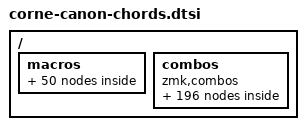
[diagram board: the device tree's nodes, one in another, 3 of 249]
/* Auto-generated by scripts/gen-chords-dual.py — do not edit by hand */
/* CORNE-canonical dual-layout chords: 50 words × 2 layouts × 2 space keys */

/ {
    macros {
        wm_the: wm_the {
            compatible = "zmk,behavior-macro";
            #binding-cells = <0>;
            wait-ms = <0>;
            tap-ms = <0>;
            bindings = <&kp T &kp H &kp E &kp SPACE>;
        };

        wm_be: wm_be {
            compatible = "zmk,behavior-macro";
            #binding-cells = <0>;
            wait-ms = <0>;
            tap-ms = <0>;
            bindings = <&kp B &kp E &kp SPACE>;
        };

        wm_to: wm_to {
            compatible = "zmk,behavior-macro";
            #binding-cells = <0>;
            wait-ms = <0>;
            tap-ms = <0>;
            bindings = <&kp T &kp O &kp SPACE>;
        };

        wm_and: wm_and {
            compatible = "zmk,behavior-macro";
            #binding-cells = <0>;
            wait-ms = <0>;
            tap-ms = <0>;
            bindings = <&kp A &kp N &kp D &kp SPACE>;
        };

        wm_of: wm_of {
            compatible = "zmk,behavior-macro";
            #binding-cells = <0>;
            wait-ms = <0>;
            tap-ms = <0>;
            bindings = <&kp O &kp F &kp SPACE>;
        };

        wm_in: wm_in {
            compatible = "zmk,behavior-macro";
            #binding-cells = <0>;
            wait-ms = <0>;
            tap-ms = <0>;
            bindings = <&kp I &kp N &kp SPACE>;
        };

        wm_have: wm_have {
            compatible = "zmk,behavior-macro";
            #binding-cells = <0>;
            wait-ms = <0>;
            tap-ms = <0>;
            bindings = <&kp H &kp A &kp V &kp E &kp SPACE>;
        };

        wm_that: wm_that {
            compatible = "zmk,behavior-macro";
            #binding-cells = <0>;
            wait-ms = <0>;
            tap-ms = <0>;
            bindings = <&kp T &kp H &kp A &kp T &kp SPACE>;
        };

        wm_for: wm_for {
            compatible = "zmk,behavior-macro";
            #binding-cells = <0>;
            wait-ms = <0>;
            tap-ms = <0>;
            bindings = <&kp F &kp O &kp R &kp SPACE>;
        };

        wm_not: wm_not {
            compatible = "zmk,behavior-macro";
            #binding-cells = <0>;
            wait-ms = <0>;
            tap-ms = <0>;
            bindings = <&kp N &kp O &kp T &kp SPACE>;
        };

        wm_with: wm_with {
            compatible = "zmk,behavior-macro";
            #binding-cells = <0>;
            wait-ms = <0>;
            tap-ms = <0>;
            bindings = <&kp W &kp I &kp T &kp H &kp SPACE>;
        };

        wm_you: wm_you {
            compatible = "zmk,behavior-macro";
            #binding-cells = <0>;
            wait-ms = <0>;
            tap-ms = <0>;
            bindings = <&kp Y &kp O &kp U &kp SPACE>;
        };

        wm_this: wm_this {
            compatible = "zmk,behavior-macro";
            #binding-cells = <0>;
            wait-ms = <0>;
            tap-ms = <0>;
            bindings = <&kp T &kp H &kp I &kp S &kp SPACE>;
        };

        wm_from: wm_from {
            compatible = "zmk,behavior-macro";
            #binding-cells = <0>;
            wait-ms = <0>;
            tap-ms = <0>;
            bindings = <&kp F &kp R &kp O &kp M &kp SPACE>;
        };

        wm_but: wm_but {
            compatible = "zmk,behavior-macro";
            #binding-cells = <0>;
            wait-ms = <0>;
            tap-ms = <0>;
            bindings = <&kp B &kp U &kp T &kp SPACE>;
        };

        wm_what: wm_what {
            compatible = "zmk,behavior-macro";
            #binding-cells = <0>;
            wait-ms = <0>;
            tap-ms = <0>;
            bindings = <&kp W &kp H &kp A &kp T &kp SPACE>;
        };

        wm_it: wm_it {
            compatible = "zmk,behavior-macro";
            #binding-cells = <0>;
            wait-ms = <0>;
            tap-ms = <0>;
            bindings = <&kp I &kp T &kp SPACE>;
        };

        wm_he: wm_he {
            compatible = "zmk,behavior-macro";
            #binding-cells = <0>;
            wait-ms = <0>;
            tap-ms = <0>;
            bindings = <&kp H &kp E &kp SPACE>;
        };

        wm_on: wm_on {
            compatible = "zmk,behavior-macro";
            #binding-cells = <0>;
            wait-ms = <0>;
            tap-ms = <0>;
            bindings = <&kp O &kp N &kp SPACE>;
        };

        wm_are: wm_are {
            compatible = "zmk,behavior-macro";
            #binding-cells = <0>;
            wait-ms = <0>;
            tap-ms = <0>;
            bindings = <&kp A &kp R &kp E &kp SPACE>;
        };

        wm_do: wm_do {
            compatible = "zmk,behavior-macro";
            #binding-cells = <0>;
            wait-ms = <0>;
            tap-ms = <0>;
            bindings = <&kp D &kp O &kp SPACE>;
        };

        wm_his: wm_his {
            compatible = "zmk,behavior-macro";
            #binding-cells = <0>;
            wait-ms = <0>;
            tap-ms = <0>;
            bindings = <&kp H &kp I &kp S &kp SPACE>;
        };

        wm_by: wm_by {
            compatible = "zmk,behavior-macro";
            #binding-cells = <0>;
            wait-ms = <0>;
            tap-ms = <0>;
            bindings = <&kp B &kp Y &kp SPACE>;
        };

        wm_they: wm_they {
            compatible = "zmk,behavior-macro";
            #binding-cells = <0>;
            wait-ms = <0>;
            tap-ms = <0>;
            bindings = <&kp T &kp H &kp E &kp Y &kp SPACE>;
        };

        wm_her: wm_her {
            compatible = "zmk,behavior-macro";
            #binding-cells = <0>;
            wait-ms = <0>;
            tap-ms = <0>;
            bindings = <&kp H &kp E &kp R &kp SPACE>;
        };

        wm_or: wm_or {
            compatible = "zmk,behavior-macro";
            #binding-cells = <0>;
            wait-ms = <0>;
            tap-ms = <0>;
            bindings = <&kp O &kp R &kp SPACE>;
        };

        wm_at: wm_at {
            compatible = "zmk,behavior-macro";
            #binding-cells = <0>;
            wait-ms = <0>;
            tap-ms = <0>;
            bindings = <&kp A &kp T &kp SPACE>;
        };

        wm_one: wm_one {
            compatible = "zmk,behavior-macro";
            #binding-cells = <0>;
            wait-ms = <0>;
            tap-ms = <0>;
            bindings = <&kp O &kp N &kp E &kp SPACE>;
        };

        wm_had: wm_had {
            compatible = "zmk,behavior-macro";
            #binding-cells = <0>;
            wait-ms = <0>;
            tap-ms = <0>;
            bindings = <&kp H &kp A &kp D &kp SPACE>;
        };

        wm_say: wm_say {
            compatible = "zmk,behavior-macro";
            #binding-cells = <0>;
            wait-ms = <0>;
            tap-ms = <0>;
            bindings = <&kp S &kp A &kp Y &kp SPACE>;
        };

        wm_she: wm_she {
            compatible = "zmk,behavior-macro";
            #binding-cells = <0>;
            wait-ms = <0>;
            tap-ms = <0>;
            bindings = <&kp S &kp H &kp E &kp SPACE>;
        };

        wm_all: wm_all {
            compatible = "zmk,behavior-macro";
            #binding-cells = <0>;
            wait-ms = <0>;
            tap-ms = <0>;
            bindings = <&kp A &kp L &kp L &kp SPACE>;
        };

        wm_which: wm_which {
            compatible = "zmk,behavior-macro";
            #binding-cells = <0>;
            wait-ms = <0>;
            tap-ms = <0>;
            bindings = <&kp W &kp H &kp I &kp C &kp H &kp SPACE>;
        };

        wm_will: wm_will {
            compatible = "zmk,behavior-macro";
            #binding-cells = <0>;
            wait-ms = <0>;
            tap-ms = <0>;
            bindings = <&kp W &kp I &kp L &kp L &kp SPACE>;
        };

        wm_would: wm_would {
            compatible = "zmk,behavior-macro";
            #binding-cells = <0>;
            wait-ms = <0>;
            tap-ms = <0>;
            bindings = <&kp W &kp O &kp U &kp L &kp D &kp SPACE>;
        };

        wm_there: wm_there {
            compatible = "zmk,behavior-macro";
            #binding-cells = <0>;
            wait-ms = <0>;
            tap-ms = <0>;
            bindings = <&kp T &kp H &kp E &kp R &kp E &kp SPACE>;
        };

        wm_their: wm_their {
            compatible = "zmk,behavior-macro";
            #binding-cells = <0>;
            wait-ms = <0>;
            tap-ms = <0>;
            bindings = <&kp T &kp H &kp E &kp I &kp R &kp SPACE>;
        };

        wm_my: wm_my {
            compatible = "zmk,behavior-macro";
            #binding-cells = <0>;
            wait-ms = <0>;
            tap-ms = <0>;
            bindings = <&kp M &kp Y &kp SPACE>;
        };

        wm_out: wm_out {
            compatible = "zmk,behavior-macro";
            #binding-cells = <0>;
            wait-ms = <0>;
            tap-ms = <0>;
            bindings = <&kp O &kp U &kp T &kp SPACE>;
        };

        wm_up: wm_up {
            compatible = "zmk,behavior-macro";
            #binding-cells = <0>;
            wait-ms = <0>;
            tap-ms = <0>;
            bindings = <&kp U &kp P &kp SPACE>;
        };

        wm_about: wm_about {
            compatible = "zmk,behavior-macro";
            #binding-cells = <0>;
            wait-ms = <0>;
            tap-ms = <0>;
            bindings = <&kp A &kp B &kp O &kp U &kp T &kp SPACE>;
        };

        wm_who: wm_who {
            compatible = "zmk,behavior-macro";
            #binding-cells = <0>;
            wait-ms = <0>;
            tap-ms = <0>;
            bindings = <&kp W &kp H &kp O &kp SPACE>;
        };

        wm_get: wm_get {
            compatible = "zmk,behavior-macro";
            #binding-cells = <0>;
            wait-ms = <0>;
            tap-ms = <0>;
            bindings = <&kp G &kp E &kp T &kp SPACE>;
        };

        wm_make: wm_make {
            compatible = "zmk,behavior-macro";
            #binding-cells = <0>;
            wait-ms = <0>;
            tap-ms = <0>;
            bindings = <&kp M &kp A &kp K &kp E &kp SPACE>;
        };

        wm_go: wm_go {
            compatible = "zmk,behavior-macro";
            #binding-cells = <0>;
            wait-ms = <0>;
            tap-ms = <0>;
            bindings = <&kp G &kp O &kp SPACE>;
        };

        wm_like: wm_like {
            compatible = "zmk,behavior-macro";
            #binding-cells = <0>;
            wait-ms = <0>;
            tap-ms = <0>;
            bindings = <&kp L &kp I &kp K &kp E &kp SPACE>;
        };

        wm_just: wm_just {
            compatible = "zmk,behavior-macro";
            #binding-cells = <0>;
            wait-ms = <0>;
            tap-ms = <0>;
            bindings = <&kp J &kp U &kp S &kp T &kp SPACE>;
        };

        wm_know: wm_know {
            compatible = "zmk,behavior-macro";
            #binding-cells = <0>;
            wait-ms = <0>;
            tap-ms = <0>;
            bindings = <&kp K &kp N &kp O &kp W &kp SPACE>;
        };

        wm_take: wm_take {
            compatible = "zmk,behavior-macro";
            #binding-cells = <0>;
            wait-ms = <0>;
            tap-ms = <0>;
            bindings = <&kp T &kp A &kp K &kp E &kp SPACE>;
        };

        wm_come: wm_come {
            compatible = "zmk,behavior-macro";
            #binding-cells = <0>;
            wait-ms = <0>;
            tap-ms = <0>;
            bindings = <&kp C &kp O &kp M &kp E &kp SPACE>;
        };
    };

    combos {
        compatible = "zmk,combos";

        chord_the_ql {
            bindings = <&wm_the>;
            key-positions = <17 30 55>;
            timeout-ms = <50>;
            layers = <0>;
        };

        chord_the_qr {
            bindings = <&wm_the>;
            key-positions = <17 30 56>;
            timeout-ms = <50>;
            layers = <0>;
        };

        chord_the_gl {
            bindings = <&wm_the>;
            key-positions = <27 31 55>;
            timeout-ms = <50>;
            layers = <1>;
        };

        chord_the_gr {
            bindings = <&wm_the>;
            key-positions = <27 31 56>;
            timeout-ms = <50>;
            layers = <1>;
        };

        chord_be_ql {
            bindings = <&wm_be>;
            key-positions = <15 41 55>;
            timeout-ms = <50>;
            layers = <0>;
        };

        chord_be_qr {
            bindings = <&wm_be>;
            key-positions = <15 41 56>;
            timeout-ms = <50>;
            layers = <0>;
        };

        chord_be_gl {
            bindings = <&wm_be>;
            key-positions = <13 33 55>;
            timeout-ms = <50>;
            layers = <1>;
        };

        chord_be_gr {
            bindings = <&wm_be>;
            key-positions = <13 33 56>;
            timeout-ms = <50>;
            layers = <1>;
        };

        chord_to_ql {
            bindings = <&wm_to>;
            key-positions = <17 21 55>;
            timeout-ms = <50>;
            layers = <0>;
        };

        chord_to_qr {
            bindings = <&wm_to>;
            key-positions = <17 21 56>;
            timeout-ms = <50>;
            layers = <0>;
        };

        chord_to_gl {
            bindings = <&wm_to>;
            key-positions = <20 27 55>;
            timeout-ms = <50>;
            layers = <1>;
        };

        chord_to_gr {
            bindings = <&wm_to>;
            key-positions = <20 27 56>;
            timeout-ms = <50>;
            layers = <1>;
        };

        chord_and_ql {
            bindings = <&wm_and>;
            key-positions = <25 44 55>;
            timeout-ms = <50>;
            layers = <0>;
        };

        chord_and_qr {
            bindings = <&wm_and>;
            key-positions = <25 44 56>;
            timeout-ms = <50>;
            layers = <0>;
        };

        chord_and_gl {
            bindings = <&wm_and>;
            key-positions = <25 32 55>;
            timeout-ms = <50>;
            layers = <1>;
        };

        chord_and_gr {
            bindings = <&wm_and>;
            key-positions = <25 32 56>;
            timeout-ms = <50>;
            layers = <1>;
        };

        chord_of_ql {
            bindings = <&wm_of>;
            key-positions = <21 28 55>;
            timeout-ms = <50>;
            layers = <0>;
        };

        chord_of_qr {
            bindings = <&wm_of>;
            key-positions = <21 28 56>;
            timeout-ms = <50>;
            layers = <0>;
        };

        chord_of_gl {
            bindings = <&wm_of>;
            key-positions = <20 45 55>;
            timeout-ms = <50>;
            layers = <1>;
        };

        chord_of_gr {
            bindings = <&wm_of>;
            key-positions = <20 45 56>;
            timeout-ms = <50>;
            layers = <1>;
        };

        chord_in_ql {
            bindings = <&wm_in>;
            key-positions = <20 44 55>;
            timeout-ms = <50>;
            layers = <0>;
        };

        chord_in_qr {
            bindings = <&wm_in>;
            key-positions = <20 44 56>;
            timeout-ms = <50>;
            layers = <0>;
        };

        chord_in_gl {
            bindings = <&wm_in>;
            key-positions = <25 34 55>;
            timeout-ms = <50>;
            layers = <1>;
        };

        chord_in_gr {
            bindings = <&wm_in>;
            key-positions = <25 34 56>;
            timeout-ms = <50>;
            layers = <1>;
        };

        chord_have_ql {
            bindings = <&wm_have>;
            key-positions = <30 40 55>;
            timeout-ms = <50>;
            layers = <0>;
        };

        chord_have_qr {
            bindings = <&wm_have>;
            key-positions = <30 40 56>;
            timeout-ms = <50>;
            layers = <0>;
        };

        chord_have_gl {
            bindings = <&wm_have>;
            key-positions = <17 31 55>;
            timeout-ms = <50>;
            layers = <1>;
        };

        chord_have_gr {
            bindings = <&wm_have>;
            key-positions = <17 31 56>;
            timeout-ms = <50>;
            layers = <1>;
        };

        chord_that_ql {
            bindings = <&wm_that>;
            key-positions = <17 25 30 55>;
            timeout-ms = <50>;
            layers = <0>;
        };

        chord_that_qr {
            bindings = <&wm_that>;
            key-positions = <17 25 30 56>;
            timeout-ms = <50>;
            layers = <0>;
        };

        chord_that_gl {
            bindings = <&wm_that>;
            key-positions = <27 31 32 55>;
            timeout-ms = <50>;
            layers = <1>;
        };

        chord_that_gr {
            bindings = <&wm_that>;
            key-positions = <27 31 32 56>;
            timeout-ms = <50>;
            layers = <1>;
        };

        chord_for_ql {
            bindings = <&wm_for>;
            key-positions = <16 28 55>;
            timeout-ms = <50>;
            layers = <0>;
        };

        chord_for_qr {
            bindings = <&wm_for>;
            key-positions = <16 28 56>;
            timeout-ms = <50>;
            layers = <0>;
        };

        chord_for_gl {
            bindings = <&wm_for>;
            key-positions = <26 45 55>;
            timeout-ms = <50>;
            layers = <1>;
        };

        chord_for_gr {
            bindings = <&wm_for>;
            key-positions = <26 45 56>;
            timeout-ms = <50>;
            layers = <1>;
        };

        chord_not_ql {
            bindings = <&wm_not>;
            key-positions = <17 44 55>;
            timeout-ms = <50>;
            layers = <0>;
        };

        chord_not_qr {
            bindings = <&wm_not>;
            key-positions = <17 44 56>;
            timeout-ms = <50>;
            layers = <0>;
        };

        chord_not_gl {
            bindings = <&wm_not>;
            key-positions = <25 27 55>;
            timeout-ms = <50>;
            layers = <1>;
        };

        chord_not_gr {
            bindings = <&wm_not>;
            key-positions = <25 27 56>;
            timeout-ms = <50>;
            layers = <1>;
        };

        chord_with_ql {
            bindings = <&wm_with>;
            key-positions = <14 20 55>;
            timeout-ms = <50>;
            layers = <0>;
        };

        chord_with_qr {
            bindings = <&wm_with>;
            key-positions = <14 20 56>;
            timeout-ms = <50>;
            layers = <0>;
        };

        chord_with_gl {
            bindings = <&wm_with>;
            key-positions = <34 40 55>;
            timeout-ms = <50>;
            layers = <1>;
        };

        chord_with_gr {
            bindings = <&wm_with>;
            key-positions = <34 40 56>;
            timeout-ms = <50>;
            layers = <1>;
        };

        chord_you_ql {
            bindings = <&wm_you>;
            key-positions = <18 21 55>;
            timeout-ms = <50>;
            layers = <0>;
        };

        chord_you_qr {
            bindings = <&wm_you>;
            key-positions = <18 21 56>;
            timeout-ms = <50>;
            layers = <0>;
        };

        chord_you_gl {
            bindings = <&wm_you>;
            key-positions = <19 20 55>;
            timeout-ms = <50>;
            layers = <1>;
        };

        chord_you_gr {
            bindings = <&wm_you>;
            key-positions = <19 20 56>;
            timeout-ms = <50>;
            layers = <1>;
        };

        chord_this_ql {
            bindings = <&wm_this>;
            key-positions = <17 20 55>;
            timeout-ms = <50>;
            layers = <0>;
        };

        chord_this_qr {
            bindings = <&wm_this>;
            key-positions = <17 20 56>;
            timeout-ms = <50>;
            layers = <0>;
        };

        chord_this_gl {
            bindings = <&wm_this>;
            key-positions = <27 34 55>;
            timeout-ms = <50>;
            layers = <1>;
        };

        chord_this_gr {
            bindings = <&wm_this>;
            key-positions = <27 34 56>;
            timeout-ms = <50>;
            layers = <1>;
        };

        chord_from_ql {
            bindings = <&wm_from>;
            key-positions = <16 21 28 55>;
            timeout-ms = <50>;
            layers = <0>;
        };

        chord_from_qr {
            bindings = <&wm_from>;
            key-positions = <16 21 28 56>;
            timeout-ms = <50>;
            layers = <0>;
        };

        chord_from_gl {
            bindings = <&wm_from>;
            key-positions = <20 26 45 55>;
            timeout-ms = <50>;
            layers = <1>;
        };

        chord_from_gr {
            bindings = <&wm_from>;
            key-positions = <20 26 45 56>;
            timeout-ms = <50>;
            layers = <1>;
        };

        chord_but_ql {
            bindings = <&wm_but>;
            key-positions = <19 41 55>;
            timeout-ms = <50>;
            layers = <0>;
        };

        chord_but_qr {
            bindings = <&wm_but>;
            key-positions = <19 41 56>;
            timeout-ms = <50>;
            layers = <0>;
        };

        chord_but_gl {
            bindings = <&wm_but>;
            key-positions = <13 21 55>;
            timeout-ms = <50>;
            layers = <1>;
        };

        chord_but_gr {
            bindings = <&wm_but>;
            key-positions = <13 21 56>;
            timeout-ms = <50>;
            layers = <1>;
        };

        chord_what_ql {
            bindings = <&wm_what>;
            key-positions = <14 25 55>;
            timeout-ms = <50>;
            layers = <0>;
        };

        chord_what_qr {
            bindings = <&wm_what>;
            key-positions = <14 25 56>;
            timeout-ms = <50>;
            layers = <0>;
        };

        chord_what_gl {
            bindings = <&wm_what>;
            key-positions = <32 40 55>;
            timeout-ms = <50>;
            layers = <1>;
        };

        chord_what_gr {
            bindings = <&wm_what>;
            key-positions = <32 40 56>;
            timeout-ms = <50>;
            layers = <1>;
        };

        chord_he_ql {
            bindings = <&wm_he>;
            key-positions = <15 30 55>;
            timeout-ms = <50>;
            layers = <0>;
        };

        chord_he_qr {
            bindings = <&wm_he>;
            key-positions = <15 30 56>;
            timeout-ms = <50>;
            layers = <0>;
        };

        chord_he_gl {
            bindings = <&wm_he>;
            key-positions = <31 33 55>;
            timeout-ms = <50>;
            layers = <1>;
        };

        chord_he_gr {
            bindings = <&wm_he>;
            key-positions = <31 33 56>;
            timeout-ms = <50>;
            layers = <1>;
        };

        chord_on_ql {
            bindings = <&wm_on>;
            key-positions = <21 44 55>;
            timeout-ms = <50>;
            layers = <0>;
        };

        chord_on_qr {
            bindings = <&wm_on>;
            key-positions = <21 44 56>;
            timeout-ms = <50>;
            layers = <0>;
        };

        chord_on_gl {
            bindings = <&wm_on>;
            key-positions = <20 25 55>;
            timeout-ms = <50>;
            layers = <1>;
        };

        chord_on_gr {
            bindings = <&wm_on>;
            key-positions = <20 25 56>;
            timeout-ms = <50>;
            layers = <1>;
        };

        chord_are_ql {
            bindings = <&wm_are>;
            key-positions = <16 25 55>;
            timeout-ms = <50>;
            layers = <0>;
        };

        chord_are_qr {
            bindings = <&wm_are>;
            key-positions = <16 25 56>;
            timeout-ms = <50>;
            layers = <0>;
        };

        chord_are_gl {
            bindings = <&wm_are>;
            key-positions = <26 32 55>;
            timeout-ms = <50>;
            layers = <1>;
        };

        chord_are_gr {
            bindings = <&wm_are>;
            key-positions = <26 32 56>;
            timeout-ms = <50>;
            layers = <1>;
        };

        chord_do_ql {
            bindings = <&wm_do>;
            key-positions = <21 27 55>;
            timeout-ms = <50>;
            layers = <0>;
        };

        chord_do_qr {
            bindings = <&wm_do>;
            key-positions = <21 27 56>;
            timeout-ms = <50>;
            layers = <0>;
        };

        chord_do_gl {
            bindings = <&wm_do>;
            key-positions = <15 20 55>;
            timeout-ms = <50>;
            layers = <1>;
        };

        chord_do_gr {
            bindings = <&wm_do>;
            key-positions = <15 20 56>;
            timeout-ms = <50>;
            layers = <1>;
        };

        chord_his_ql {
            bindings = <&wm_his>;
            key-positions = <20 30 55>;
            timeout-ms = <50>;
            layers = <0>;
        };

        chord_his_qr {
            bindings = <&wm_his>;
            key-positions = <20 30 56>;
            timeout-ms = <50>;
            layers = <0>;
        };

        chord_his_gl {
            bindings = <&wm_his>;
            key-positions = <31 34 55>;
            timeout-ms = <50>;
            layers = <1>;
        };

        chord_his_gr {
            bindings = <&wm_his>;
            key-positions = <31 34 56>;
            timeout-ms = <50>;
            layers = <1>;
        };

        chord_by_ql {
            bindings = <&wm_by>;
            key-positions = <18 41 55>;
            timeout-ms = <50>;
            layers = <0>;
        };

        chord_by_qr {
            bindings = <&wm_by>;
            key-positions = <18 41 56>;
            timeout-ms = <50>;
            layers = <0>;
        };

        chord_by_gl {
            bindings = <&wm_by>;
            key-positions = <13 19 55>;
            timeout-ms = <50>;
            layers = <1>;
        };

        chord_by_gr {
            bindings = <&wm_by>;
            key-positions = <13 19 56>;
            timeout-ms = <50>;
            layers = <1>;
        };

        chord_they_ql {
            bindings = <&wm_they>;
            key-positions = <17 18 55>;
            timeout-ms = <50>;
            layers = <0>;
        };

        chord_they_qr {
            bindings = <&wm_they>;
            key-positions = <17 18 56>;
            timeout-ms = <50>;
            layers = <0>;
        };

        chord_they_gl {
            bindings = <&wm_they>;
            key-positions = <19 27 55>;
            timeout-ms = <50>;
            layers = <1>;
        };

        chord_they_gr {
            bindings = <&wm_they>;
            key-positions = <19 27 56>;
            timeout-ms = <50>;
            layers = <1>;
        };

        chord_her_ql {
            bindings = <&wm_her>;
            key-positions = <16 30 55>;
            timeout-ms = <50>;
            layers = <0>;
        };

        chord_her_qr {
            bindings = <&wm_her>;
            key-positions = <16 30 56>;
            timeout-ms = <50>;
            layers = <0>;
        };

        chord_her_gl {
            bindings = <&wm_her>;
            key-positions = <26 31 55>;
            timeout-ms = <50>;
            layers = <1>;
        };

        chord_her_gr {
            bindings = <&wm_her>;
            key-positions = <26 31 56>;
            timeout-ms = <50>;
            layers = <1>;
        };

        chord_or_ql {
            bindings = <&wm_or>;
            key-positions = <16 21 55>;
            timeout-ms = <50>;
            layers = <0>;
        };

        chord_or_qr {
            bindings = <&wm_or>;
            key-positions = <16 21 56>;
            timeout-ms = <50>;
            layers = <0>;
        };

        chord_or_gl {
            bindings = <&wm_or>;
            key-positions = <20 26 55>;
            timeout-ms = <50>;
            layers = <1>;
        };

        chord_or_gr {
            bindings = <&wm_or>;
            key-positions = <20 26 56>;
            timeout-ms = <50>;
            layers = <1>;
        };

        chord_at_ql {
            bindings = <&wm_at>;
            key-positions = <17 25 55>;
            timeout-ms = <50>;
            layers = <0>;
        };

        chord_at_qr {
            bindings = <&wm_at>;
            key-positions = <17 25 56>;
            timeout-ms = <50>;
            layers = <0>;
        };

        chord_at_gl {
            bindings = <&wm_at>;
            key-positions = <27 32 55>;
            timeout-ms = <50>;
            layers = <1>;
        };

        chord_at_gr {
            bindings = <&wm_at>;
            key-positions = <27 32 56>;
            timeout-ms = <50>;
            layers = <1>;
        };

        chord_one_ql {
            bindings = <&wm_one>;
            key-positions = <15 21 55>;
            timeout-ms = <50>;
            layers = <0>;
        };

        chord_one_qr {
            bindings = <&wm_one>;
            key-positions = <15 21 56>;
            timeout-ms = <50>;
            layers = <0>;
        };

        chord_one_gl {
            bindings = <&wm_one>;
            key-positions = <20 33 55>;
            timeout-ms = <50>;
            layers = <1>;
        };

        chord_one_gr {
            bindings = <&wm_one>;
            key-positions = <20 33 56>;
            timeout-ms = <50>;
            layers = <1>;
        };

        chord_had_ql {
            bindings = <&wm_had>;
            key-positions = <27 30 55>;
            timeout-ms = <50>;
            layers = <0>;
        };

        chord_had_qr {
            bindings = <&wm_had>;
            key-positions = <27 30 56>;
            timeout-ms = <50>;
            layers = <0>;
        };

        chord_had_gl {
            bindings = <&wm_had>;
            key-positions = <15 31 55>;
            timeout-ms = <50>;
            layers = <1>;
        };

        chord_had_gr {
            bindings = <&wm_had>;
            key-positions = <15 31 56>;
            timeout-ms = <50>;
            layers = <1>;
        };

        chord_say_ql {
            bindings = <&wm_say>;
            key-positions = <18 26 55>;
            timeout-ms = <50>;
            layers = <0>;
        };

        chord_say_qr {
            bindings = <&wm_say>;
            key-positions = <18 26 56>;
            timeout-ms = <50>;
            layers = <0>;
        };

        chord_say_gl {
            bindings = <&wm_say>;
            key-positions = <19 28 55>;
            timeout-ms = <50>;
            layers = <1>;
        };

        chord_say_gr {
            bindings = <&wm_say>;
            key-positions = <19 28 56>;
            timeout-ms = <50>;
            layers = <1>;
        };

        chord_she_ql {
            bindings = <&wm_she>;
            key-positions = <26 30 55>;
            timeout-ms = <50>;
            layers = <0>;
        };

        chord_she_qr {
            bindings = <&wm_she>;
            key-positions = <26 30 56>;
            timeout-ms = <50>;
            layers = <0>;
        };

        chord_she_gl {
            bindings = <&wm_she>;
            key-positions = <28 31 55>;
            timeout-ms = <50>;
            layers = <1>;
        };

        chord_she_gr {
            bindings = <&wm_she>;
            key-positions = <28 31 56>;
            timeout-ms = <50>;
            layers = <1>;
        };

        chord_all_ql {
            bindings = <&wm_all>;
            key-positions = <25 33 55>;
            timeout-ms = <50>;
            layers = <0>;
        };

        chord_all_qr {
            bindings = <&wm_all>;
            key-positions = <25 33 56>;
            timeout-ms = <50>;
            layers = <0>;
        };

        chord_all_gl {
            bindings = <&wm_all>;
            key-positions = <14 32 55>;
            timeout-ms = <50>;
            layers = <1>;
        };

        chord_all_gr {
            bindings = <&wm_all>;
            key-positions = <14 32 56>;
            timeout-ms = <50>;
            layers = <1>;
        };

        chord_which_ql {
            bindings = <&wm_which>;
            key-positions = <14 30 55>;
            timeout-ms = <50>;
            layers = <0>;
        };

        chord_which_qr {
            bindings = <&wm_which>;
            key-positions = <14 30 56>;
            timeout-ms = <50>;
            layers = <0>;
        };

        chord_which_gl {
            bindings = <&wm_which>;
            key-positions = <31 40 55>;
            timeout-ms = <50>;
            layers = <1>;
        };

        chord_which_gr {
            bindings = <&wm_which>;
            key-positions = <31 40 56>;
            timeout-ms = <50>;
            layers = <1>;
        };

        chord_will_ql {
            bindings = <&wm_will>;
            key-positions = <14 33 55>;
            timeout-ms = <50>;
            layers = <0>;
        };

        chord_will_qr {
            bindings = <&wm_will>;
            key-positions = <14 33 56>;
            timeout-ms = <50>;
            layers = <0>;
        };

        chord_will_gl {
            bindings = <&wm_will>;
            key-positions = <14 40 55>;
            timeout-ms = <50>;
            layers = <1>;
        };

        chord_will_gr {
            bindings = <&wm_will>;
            key-positions = <14 40 56>;
            timeout-ms = <50>;
            layers = <1>;
        };

        chord_would_ql {
            bindings = <&wm_would>;
            key-positions = <14 27 55>;
            timeout-ms = <50>;
            layers = <0>;
        };

        chord_would_qr {
            bindings = <&wm_would>;
            key-positions = <14 27 56>;
            timeout-ms = <50>;
            layers = <0>;
        };

        chord_would_gl {
            bindings = <&wm_would>;
            key-positions = <15 40 55>;
            timeout-ms = <50>;
            layers = <1>;
        };

        chord_would_gr {
            bindings = <&wm_would>;
            key-positions = <15 40 56>;
            timeout-ms = <50>;
            layers = <1>;
        };

        chord_there_ql {
            bindings = <&wm_there>;
            key-positions = <16 17 55>;
            timeout-ms = <50>;
            layers = <0>;
        };

        chord_there_qr {
            bindings = <&wm_there>;
            key-positions = <16 17 56>;
            timeout-ms = <50>;
            layers = <0>;
        };

        chord_there_gl {
            bindings = <&wm_there>;
            key-positions = <26 27 55>;
            timeout-ms = <50>;
            layers = <1>;
        };

        chord_there_gr {
            bindings = <&wm_there>;
            key-positions = <26 27 56>;
            timeout-ms = <50>;
            layers = <1>;
        };

        chord_their_ql {
            bindings = <&wm_their>;
            key-positions = <15 17 20 55>;
            timeout-ms = <50>;
            layers = <0>;
        };

        chord_their_qr {
            bindings = <&wm_their>;
            key-positions = <15 17 20 56>;
            timeout-ms = <50>;
            layers = <0>;
        };

        chord_their_gl {
            bindings = <&wm_their>;
            key-positions = <27 33 34 55>;
            timeout-ms = <50>;
            layers = <1>;
        };

        chord_their_gr {
            bindings = <&wm_their>;
            key-positions = <27 33 34 56>;
            timeout-ms = <50>;
            layers = <1>;
        };

        chord_my_ql {
            bindings = <&wm_my>;
            key-positions = <18 45 55>;
            timeout-ms = <50>;
            layers = <0>;
        };

        chord_my_qr {
            bindings = <&wm_my>;
            key-positions = <18 45 56>;
            timeout-ms = <50>;
            layers = <0>;
        };

        chord_my_gl {
            bindings = <&wm_my>;
            key-positions = <19 39 55>;
            timeout-ms = <50>;
            layers = <1>;
        };

        chord_my_gr {
            bindings = <&wm_my>;
            key-positions = <19 39 56>;
            timeout-ms = <50>;
            layers = <1>;
        };

        chord_out_ql {
            bindings = <&wm_out>;
            key-positions = <19 21 55>;
            timeout-ms = <50>;
            layers = <0>;
        };

        chord_out_qr {
            bindings = <&wm_out>;
            key-positions = <19 21 56>;
            timeout-ms = <50>;
            layers = <0>;
        };

        chord_out_gl {
            bindings = <&wm_out>;
            key-positions = <20 21 55>;
            timeout-ms = <50>;
            layers = <1>;
        };

        chord_out_gr {
            bindings = <&wm_out>;
            key-positions = <20 21 56>;
            timeout-ms = <50>;
            layers = <1>;
        };

        chord_up_ql {
            bindings = <&wm_up>;
            key-positions = <19 22 55>;
            timeout-ms = <50>;
            layers = <0>;
        };

        chord_up_qr {
            bindings = <&wm_up>;
            key-positions = <19 22 56>;
            timeout-ms = <50>;
            layers = <0>;
        };

        chord_up_gl {
            bindings = <&wm_up>;
            key-positions = <21 30 55>;
            timeout-ms = <50>;
            layers = <1>;
        };

        chord_up_gr {
            bindings = <&wm_up>;
            key-positions = <21 30 56>;
            timeout-ms = <50>;
            layers = <1>;
        };

        chord_about_ql {
            bindings = <&wm_about>;
            key-positions = <25 41 55>;
            timeout-ms = <50>;
            layers = <0>;
        };

        chord_about_qr {
            bindings = <&wm_about>;
            key-positions = <25 41 56>;
            timeout-ms = <50>;
            layers = <0>;
        };

        chord_about_gl {
            bindings = <&wm_about>;
            key-positions = <13 32 55>;
            timeout-ms = <50>;
            layers = <1>;
        };

        chord_about_gr {
            bindings = <&wm_about>;
            key-positions = <13 32 56>;
            timeout-ms = <50>;
            layers = <1>;
        };

        chord_who_ql {
            bindings = <&wm_who>;
            key-positions = <14 21 55>;
            timeout-ms = <50>;
            layers = <0>;
        };

        chord_who_qr {
            bindings = <&wm_who>;
            key-positions = <14 21 56>;
            timeout-ms = <50>;
            layers = <0>;
        };

        chord_who_gl {
            bindings = <&wm_who>;
            key-positions = <20 40 55>;
            timeout-ms = <50>;
            layers = <1>;
        };

        chord_who_gr {
            bindings = <&wm_who>;
            key-positions = <20 40 56>;
            timeout-ms = <50>;
            layers = <1>;
        };

        chord_get_ql {
            bindings = <&wm_get>;
            key-positions = <15 29 55>;
            timeout-ms = <50>;
            layers = <0>;
        };

        chord_get_qr {
            bindings = <&wm_get>;
            key-positions = <15 29 56>;
            timeout-ms = <50>;
            layers = <0>;
        };

        chord_get_gl {
            bindings = <&wm_get>;
            key-positions = <29 33 55>;
            timeout-ms = <50>;
            layers = <1>;
        };

        chord_get_gr {
            bindings = <&wm_get>;
            key-positions = <29 33 56>;
            timeout-ms = <50>;
            layers = <1>;
        };

        chord_make_ql {
            bindings = <&wm_make>;
            key-positions = <32 45 55>;
            timeout-ms = <50>;
            layers = <0>;
        };

        chord_make_qr {
            bindings = <&wm_make>;
            key-positions = <32 45 56>;
            timeout-ms = <50>;
            layers = <0>;
        };

        chord_make_gl {
            bindings = <&wm_make>;
            key-positions = <39 44 55>;
            timeout-ms = <50>;
            layers = <1>;
        };

        chord_make_gr {
            bindings = <&wm_make>;
            key-positions = <39 44 56>;
            timeout-ms = <50>;
            layers = <1>;
        };

        chord_go_ql {
            bindings = <&wm_go>;
            key-positions = <21 29 55>;
            timeout-ms = <50>;
            layers = <0>;
        };

        chord_go_qr {
            bindings = <&wm_go>;
            key-positions = <21 29 56>;
            timeout-ms = <50>;
            layers = <0>;
        };

        chord_go_gl {
            bindings = <&wm_go>;
            key-positions = <20 29 55>;
            timeout-ms = <50>;
            layers = <1>;
        };

        chord_go_gr {
            bindings = <&wm_go>;
            key-positions = <20 29 56>;
            timeout-ms = <50>;
            layers = <1>;
        };

        chord_like_ql {
            bindings = <&wm_like>;
            key-positions = <32 33 55>;
            timeout-ms = <50>;
            layers = <0>;
        };

        chord_like_qr {
            bindings = <&wm_like>;
            key-positions = <32 33 56>;
            timeout-ms = <50>;
            layers = <0>;
        };

        chord_like_gl {
            bindings = <&wm_like>;
            key-positions = <14 44 55>;
            timeout-ms = <50>;
            layers = <1>;
        };

        chord_like_gr {
            bindings = <&wm_like>;
            key-positions = <14 44 56>;
            timeout-ms = <50>;
            layers = <1>;
        };

        chord_just_ql {
            bindings = <&wm_just>;
            key-positions = <19 31 55>;
            timeout-ms = <50>;
            layers = <0>;
        };

        chord_just_qr {
            bindings = <&wm_just>;
            key-positions = <19 31 56>;
            timeout-ms = <50>;
            layers = <0>;
        };

        chord_just_gl {
            bindings = <&wm_just>;
            key-positions = <18 21 55>;
            timeout-ms = <50>;
            layers = <1>;
        };

        chord_just_gr {
            bindings = <&wm_just>;
            key-positions = <18 21 56>;
            timeout-ms = <50>;
            layers = <1>;
        };

        chord_know_ql {
            bindings = <&wm_know>;
            key-positions = <32 44 55>;
            timeout-ms = <50>;
            layers = <0>;
        };

        chord_know_qr {
            bindings = <&wm_know>;
            key-positions = <32 44 56>;
            timeout-ms = <50>;
            layers = <0>;
        };

        chord_know_gl {
            bindings = <&wm_know>;
            key-positions = <25 44 55>;
            timeout-ms = <50>;
            layers = <1>;
        };

        chord_know_gr {
            bindings = <&wm_know>;
            key-positions = <25 44 56>;
            timeout-ms = <50>;
            layers = <1>;
        };

        chord_take_ql {
            bindings = <&wm_take>;
            key-positions = <17 32 55>;
            timeout-ms = <50>;
            layers = <0>;
        };

        chord_take_qr {
            bindings = <&wm_take>;
            key-positions = <17 32 56>;
            timeout-ms = <50>;
            layers = <0>;
        };

        chord_take_gl {
            bindings = <&wm_take>;
            key-positions = <27 44 55>;
            timeout-ms = <50>;
            layers = <1>;
        };

        chord_take_gr {
            bindings = <&wm_take>;
            key-positions = <27 44 56>;
            timeout-ms = <50>;
            layers = <1>;
        };

        chord_come_ql {
            bindings = <&wm_come>;
            key-positions = <39 45 55>;
            timeout-ms = <50>;
            layers = <0>;
        };

        chord_come_qr {
            bindings = <&wm_come>;
            key-positions = <39 45 56>;
            timeout-ms = <50>;
            layers = <0>;
        };

        chord_come_gl {
            bindings = <&wm_come>;
            key-positions = <16 39 55>;
            timeout-ms = <50>;
            layers = <1>;
        };

        chord_come_gr {
            bindings = <&wm_come>;
            key-positions = <16 39 56>;
            timeout-ms = <50>;
            layers = <1>;
        };
    };
};
